# STM32H757_CM7 register map
File version: 1.3
CPU: CM7 r0p1, little endian, MPU, FPU, 4 interrupt priority bits
Registers are 32-bit, read-write, reset 0x0 unless marked. A register's access mark holds for its fields unless they carry their own. Offsets are from the block's base; [hi:lo] are bit positions; lines under a group give offsets from that group; {n}, {i} and the like mark numbered series; <NAME> marks a mode.

## SAI4 — SAI
Base 0x58005400
Same registers: SAI1 0x40015800, SAI2 0x40015C00, SAI3 0x40016000
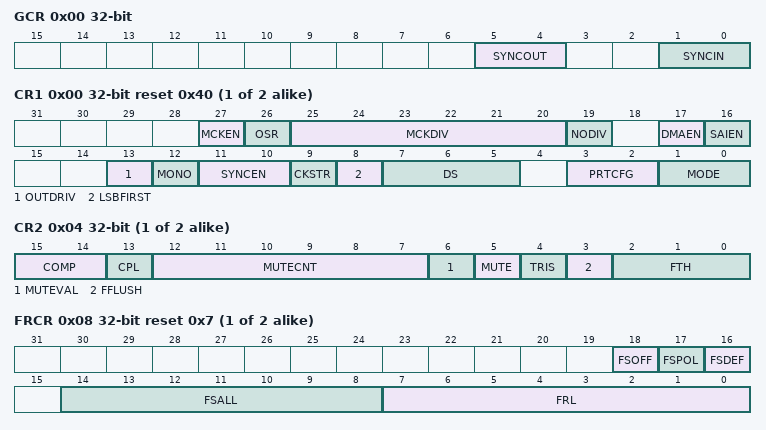
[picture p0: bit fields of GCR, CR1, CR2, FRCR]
0x00 GCR — Global configuration register
  [5:4] SYNCOUT — Synchronization outputs These bits are set and cleared by software.
  [1:0] SYNCIN — Synchronization inputs
0x04 CH{x} (x=A,B; step 0x20) group — Cluster CH{x}, containing ?CR1, ?CR2, ?FRCR, ?SLOTR, ?IM, ?SR, ?CLRFR, ?DR
  0x00 CR1 reset 0x40 — Configuration register 1
    [27] MCKEN — Master clock generation enable
    [26] OSR — Oversampling ratio for master clock
    [25:20] MCKDIV — Master clock divider. These bits are set and cleared by software. These bits are meaningless when the audio block operates in slave mode. They have to be configured when the audio block is disabled. Others: the master clock frequency is calculated accordingly to the following formula:
    [19] NODIV — No fixed divider between MCLK and FS
      0=MasterClock (MCLK output is enabled. Forces the ratio between FS and MCLK to 256 or 512 according to the OSR value); 1=NoDiv (MCLK output enable set by the MCKEN bit (where present, else 0). Ratio between FS and MCLK depends on FRL.)
    [17] DMAEN — DMA enable. This bit is set and cleared by software. Note: Since the audio block defaults to operate as a transmitter after reset, the MODE[1:0] bits must be configured before setting DMAEN to avoid a DMA request in receiver mode.
      0=Disabled (DMA disabled); 1=Enabled (DMA enabled)
    [16] SAIEN — Audio block enable where x is A or B. This bit is set by software. To switch off the audio block, the application software must program this bit to 0 and poll the bit till it reads back 0, meaning that the block is completely disabled. Before setting this bit to 1, check that it is set to 0, otherwise the enable command will not be taken into account. This bit allows to control the state of SAIx audio block. If it is disabled when an audio frame transfer is ongoing, the ongoing transfer completes and the cell is fully disabled at the end of this audio frame transfer. Note: When SAIx block is configured in master mode, the clock must be present on the input of SAIx before setting SAIXEN bit.
      0=Disabled (SAI audio block disabled); 1=Enabled (SAI audio block enabled)
    [13] OUTDRIV — Output drive. This bit is set and cleared by software. Note: This bit has to be set before enabling the audio block and after the audio block configuration.
      0=OnStart (Audio block output driven when SAIEN is set); 1=Immediately (Audio block output driven immediately after the setting of this bit)
    [12] MONO — Mono mode. This bit is set and cleared by software. It is meaningful only when the number of slots is equal to 2. When the mono mode is selected, slot 0 data are duplicated on slot 1 when the audio block operates as a transmitter. In reception mode, the slot1 is discarded and only the data received from slot 0 are stored. Refer to Section: Mono/stereo mode for more details.
      0=Stereo mode; 1=Mono mode
    [11:10] SYNCEN — Synchronization enable. These bits are set and cleared by software. They must be configured when the audio sub-block is disabled. Note: The audio sub-block should be configured as asynchronous when SPDIF mode is enabled.
      0=Asynchronous (audio sub-block in asynchronous mode); 1=Internal (audio sub-block is synchronous with the other internal audio sub-block. In this case, the audio sub-block must be configured in slave mode); 2=External (audio sub-block is synchronous with an external SAI embedded peripheral. In this case the audio sub-block should be configured in Slave mode)
    [9] CKSTR — Clock strobing edge. This bit is set and cleared by software. It must be configured when the audio block is disabled. This bit has no meaning in SPDIF audio protocol.
      0=FallingEdge (Data strobing edge is falling edge of SCK); 1=RisingEdge (Data strobing edge is rising edge of SCK)
    [8] LSBFIRST — Least significant bit first. This bit is set and cleared by software. It must be configured when the audio block is disabled. This bit has no meaning in AC97 audio protocol since AC97 data are always transferred with the MSB first. This bit has no meaning in SPDIF audio protocol since in SPDIF data are always transferred with LSB first.
      0=MsbFirst (Data are transferred with MSB first); 1=LsbFirst (Data are transferred with LSB first)
    [7:5] DS — Data size. These bits are set and cleared by software. These bits are ignored when the SPDIF protocols are selected (bit PRTCFG[1:0]), because the frame and the data size are fixed in such case. When the companding mode is selected through COMP[1:0] bits, DS[1:0] are ignored since the data size is fixed to 8 bits by the algorithm. These bits must be configured when the audio block is disabled.
      2=Bit8 (8 bits); 3=Bit10 (10 bits); 4=Bit16 (16 bits); 5=Bit20 (20 bits); 6=Bit24 (24 bits); 7=Bit32 (32 bits)
    [3:2] PRTCFG — Protocol configuration. These bits are set and cleared by software. These bits have to be configured when the audio block is disabled.
      0=Free protocol. Free protocol allows to use the powerful configuration of the audio block to address a specific audio protocol; 1=SPDIF protocol; 2=AC’97 protocol
    [1:0] MODE — SAIx audio block mode immediately
      0=MasterTx (Master transmitter); 1=MasterRx (Master receiver); 2=SlaveTx (Slave transmitter); 3=SlaveRx (Slave receiver)
  0x04 CR2 access per field — Configuration register 2
    [15:14] COMP rw — Companding mode. These bits are set and cleared by software. The -Law and the A-Law log are a part of the CCITT G.711 recommendation, the type of complement that will be used depends on CPL bit. The data expansion or data compression are determined by the state of bit MODE[0]. The data compression is applied if the audio block is configured as a transmitter. The data expansion is automatically applied when the audio block is configured as a receiver. Refer to Section: Companding mode for more details. Note: Companding mode is applicable only when TDM is selected.
      0=No companding algorithm; 2=MuLaw (μ-Law algorithm); 3=A-Law algorithm
    [13] CPL rw — Complement bit. This bit is set and cleared by software. It defines the type of complement to be used for companding mode Note: This bit has effect only when the companding mode is -Law algorithm or A-Law algorithm.
      0=OnesComplement (1’s complement representation); 1=TwosComplement (2’s complement representation)
    [12:7] MUTECNT rw — Mute counter. These bits are set and cleared by software. They are used only in reception mode. The value set in these bits is compared to the number of consecutive mute frames detected in reception. When the number of mute frames is equal to this value, the flag MUTEDET will be set and an interrupt will be generated if bit MUTEDETIE is set. Refer to Section: Mute mode for more details.
    [6] MUTEVAL rw — Mute value. This bit is set and cleared by software.It must be written before enabling the audio block: SAIXEN. This bit is meaningful only when the audio block operates as a transmitter, the number of slots is lower or equal to 2 and the MUTE bit is set. If more slots are declared, the bit value sent during the transmission in mute mode is equal to 0, whatever the value of MUTEVAL. if the number of slot is lower or equal to 2 and MUTEVAL = 1, the MUTE value transmitted for each slot is the one sent during the previous frame. Refer to Section: Mute mode for more details. Note: This bit is meaningless and should not be used for SPDIF audio blocks.
      0=SendZero (Bit value 0 is sent during the mute mode); 1=SendLast (Last values are sent during the mute mode)
    [5] MUTE rw — Mute. This bit is set and cleared by software. It is meaningful only when the audio block operates as a transmitter. The MUTE value is linked to value of MUTEVAL if the number of slots is lower or equal to 2, or equal to 0 if it is greater than 2. Refer to Section: Mute mode for more details. Note: This bit is meaningless and should not be used for SPDIF audio blocks.
      0=Disabled (No mute mode); 1=Enabled (Mute mode enabled)
    [4] TRIS rw — Tristate management on data line. This bit is set and cleared by software. It is meaningful only if the audio block is configured as a transmitter. This bit is not used when the audio block is configured in SPDIF mode. It should be configured when SAI is disabled. Refer to Section: Output data line management on an inactive slot for more details.
    [3] FFLUSH wo — FIFO flush. This bit is set by software. It is always read as 0. This bit should be configured when the SAI is disabled.
      0=NoFlush (No FIFO flush); 1=Flush (FIFO flush. Programming this bit to 1 triggers the FIFO Flush. All the internal FIFO pointers (read and write) are cleared)
    [2:0] FTH rw — FIFO threshold. This bit is set and cleared by software.
      0=Empty (FIFO empty); 1=Quarter1 (1⁄4 FIFO); 2=Quarter2 (1⁄2 FIFO); 3=Quarter3 (3⁄4 FIFO); 4=Full (FIFO full)
  0x08 FRCR reset 0x7 — This register has no meaning in AC97 and SPDIF audio protocol
    [18] FSOFF — Frame synchronization offset. This bit is set and cleared by software. It is meaningless and is not used in AC97 or SPDIF audio block configuration. This bit must be configured when the audio block is disabled.
      0=OnFirst (FS is asserted on the first bit of the slot 0); 1=BeforeFirst (FS is asserted one bit before the first bit of the slot 0)
    [17] FSPOL — Frame synchronization polarity. This bit is set and cleared by software. It is used to configure the level of the start of frame on the FS signal. It is meaningless and is not used in AC97 or SPDIF audio block configuration. This bit must be configured when the audio block is disabled.
      0=FallingEdge (FS is active low (falling edge)); 1=RisingEdge (FS is active high (rising edge))
    [16] FSDEF — Frame synchronization definition. This bit is set and cleared by software. When the bit is set, the number of slots defined in the SAI_xSLOTR register has to be even. It means that half of this number of slots will be dedicated to the left channel and the other slots for the right channel (e.g: this bit has to be set for I2S or MSB/LSB-justified protocols...). This bit is meaningless and is not used in AC97 or SPDIF audio block configuration. It must be configured when the audio block is disabled.
    [14:8] FSALL — Frame synchronization active level length. These bits are set and cleared by software. They specify the length in number of bit clock (SCK) + 1 (FSALL[6:0] + 1) of the active level of the FS signal in the audio frame These bits are meaningless and are not used in AC97 or SPDIF audio block configuration. They must be configured when the audio block is disabled.
    [7:0] FRL — Frame length. These bits are set and cleared by software. They define the audio frame length expressed in number of SCK clock cycles: the number of bits in the frame is equal to FRL[7:0] + 1. The minimum number of bits to transfer in an audio frame must be equal to 8, otherwise the audio block will behaves in an unexpected way. This is the case when the data size is 8 bits and only one slot 0 is defined in NBSLOT[4:0] of SAI_xSLOTR register (NBSLOT[3:0] = 0000). In master mode, if the master clock (available on MCLK_x pin) is used, the frame length should be aligned with a number equal to a power of 2, ranging from 8 to 256. When the master clock is not used (NODIV = 1), it is recommended to program the frame length to an value ranging from 8 to 256. These bits are meaningless and are not used in AC97 or SPDIF audio block configuration.
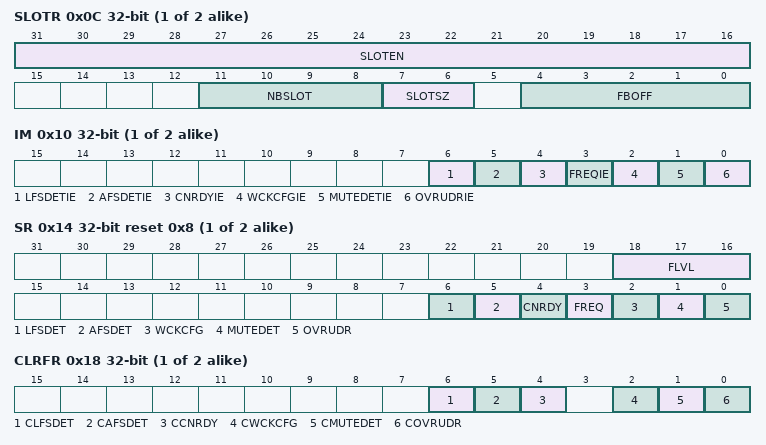
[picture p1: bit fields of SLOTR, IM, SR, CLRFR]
  0x0C SLOTR — This register has no meaning in AC97 and SPDIF audio protocol
    [31:16] SLOTEN — Slot enable. These bits are set and cleared by software. Each SLOTEN bit corresponds to a slot position from 0 to 15 (maximum 16 slots). The slot must be enabled when the audio block is disabled. They are ignored in AC97 or SPDIF mode.
      0=Inactive slot; 1=Active slot
    [11:8] NBSLOT — Number of slots in an audio frame. These bits are set and cleared by software. The value set in this bitfield represents the number of slots + 1 in the audio frame (including the number of inactive slots). The maximum number of slots is 16. The number of slots should be even if FSDEF bit in the SAI_xFRCR register is set. The number of slots must be configured when the audio block is disabled. They are ignored in AC97 or SPDIF mode.
    [7:6] SLOTSZ — Slot size This bits is set and cleared by software. The slot size must be higher or equal to the data size. If this condition is not respected, the behavior of the SAI will be undetermined. Refer to Section: Output data line management on an inactive slot for information on how to drive SD line. These bits must be set when the audio block is disabled. They are ignored in AC97 or SPDIF mode.
      0=DataSize (The slot size is equivalent to the data size (specified in DS[3:0] in the SAI_xCR1 register)); 1=Bit16 (16-bit); 2=Bit32 (32-bit)
    [4:0] FBOFF — First bit offset These bits are set and cleared by software. The value set in this bitfield defines the position of the first data transfer bit in the slot. It represents an offset value. In transmission mode, the bits outside the data field are forced to 0. In reception mode, the extra received bits are discarded. These bits must be set when the audio block is disabled. They are ignored in AC97 or SPDIF mode.
  0x10 IM — Interrupt mask register 2
    [all] fields
      0=Disabled (Interrupt is disabled); 1=Enabled (Interrupt is enabled)
    [6] LFSDETIE — Late frame synchronization detection interrupt enable. This bit is set and cleared by software. When this bit is set, an interrupt will be generated if the LFSDET bit is set in the SAI_xSR register. This bit is meaningless in AC97, SPDIF mode or when the audio block operates as a master.
    [5] AFSDETIE — Anticipated frame synchronization detection interrupt enable. This bit is set and cleared by software. When this bit is set, an interrupt will be generated if the AFSDET bit in the SAI_xSR register is set. This bit is meaningless in AC97, SPDIF mode or when the audio block operates as a master.
    [4] CNRDYIE — Codec not ready interrupt enable (AC97). This bit is set and cleared by software. When the interrupt is enabled, the audio block detects in the slot 0 (tag0) of the AC97 frame if the Codec connected to this line is ready or not. If it is not ready, the CNRDY flag in the SAI_xSR register is set and an interruption i generated. This bit has a meaning only if the AC97 mode is selected through PRTCFG[1:0] bits and the audio block is operates as a receiver.
    [3] FREQIE — FIFO request interrupt enable. This bit is set and cleared by software. When this bit is set, an interrupt is generated if the FREQ bit in the SAI_xSR register is set. Since the audio block defaults to operate as a transmitter after reset, the MODE bit must be configured before setting FREQIE to avoid a parasitic interruption in receiver mode,
    [2] WCKCFGIE — Wrong clock configuration interrupt enable. This bit is set and cleared by software. This bit is taken into account only if the audio block is configured as a master (MODE[1] = 0) and NODIV = 0. It generates an interrupt if the WCKCFG flag in the SAI_xSR register is set. Note: This bit is used only in TDM mode and is meaningless in other modes.
    [1] MUTEDETIE — Mute detection interrupt enable. This bit is set and cleared by software. When this bit is set, an interrupt is generated if the MUTEDET bit in the SAI_xSR register is set. This bit has a meaning only if the audio block is configured in receiver mode.
    [0] OVRUDRIE — Overrun/underrun interrupt enable. This bit is set and cleared by software. When this bit is set, an interrupt is generated if the OVRUDR bit in the SAI_xSR register is set.
  0x14 SR ro reset 0x8 — Status register
    [18:16] FLVL — FIFO level threshold. This bit is read only. The FIFO level threshold flag is managed only by hardware and its setting depends on SAI block configuration (transmitter or receiver mode). If the SAI block is configured as transmitter: If SAI block is configured as receiver:
      on read: 0=Empty (FIFO empty); 1=Quarter1 (FIFO <= 1⁄4 but not empty); 2=Quarter2 (1⁄4 < FIFO <= 1⁄2); 3=Quarter3 (1⁄2 < FIFO <= 3⁄4); 4=Quarter4 (3⁄4 < FIFO but not full); 5=Full (FIFO full)
    [6] LFSDET — Late frame synchronization detection. This bit is read only. This flag can be set only if the audio block is configured in slave mode. It is not used in AC97 or SPDIF mode. It can generate an interrupt if LFSDETIE bit is set in the SAI_xIM register. This flag is cleared when the software sets bit CLFSDET in SAI_xCLRFR register
      on read: 0=NoError; 1=NoSync (Frame synchronization signal is not present at the right time)
    [5] AFSDET — Anticipated frame synchronization detection. This bit is read only. This flag can be set only if the audio block is configured in slave mode. It is not used in AC97or SPDIF mode. It can generate an interrupt if AFSDETIE bit is set in SAI_xIM register. This flag is cleared when the software sets CAFSDET bit in SAI_xCLRFR register.
      on read: 0=NoError; 1=EarlySync (Frame synchronization signal is detected earlier than expected)
    [4] CNRDY — Codec not ready. This bit is read only. This bit is used only when the AC97 audio protocol is selected in the SAI_xCR1 register and configured in receiver mode. It can generate an interrupt if CNRDYIE bit is set in SAI_xIM register. This flag is cleared when the software sets CCNRDY bit in SAI_xCLRFR register.
      on read: 0=Ready (External AC’97 Codec is ready); 1=NotReady (External AC’97 Codec is not ready)
    [3] FREQ — FIFO request. This bit is read only. The request depends on the audio block configuration: If the block is configured in transmission mode, the FIFO request is related to a write request operation in the SAI_xDR. If the block configured in reception, the FIFO request related to a read request operation from the SAI_xDR. This flag can generate an interrupt if FREQIE bit is set in SAI_xIM register.
      on read: 0=NoRequest (No FIFO request); 1=Request (FIFO request to read or to write the SAI_xDR)
    [2] WCKCFG — Wrong clock configuration flag. This bit is read only. This bit is used only when the audio block operates in master mode (MODE[1] = 0) and NODIV = 0. It can generate an interrupt if WCKCFGIE bit is set in SAI_xIM register. This flag is cleared when the software sets CWCKCFG bit in SAI_xCLRFR register.
      on read: 0=Correct (Clock configuration is correct); 1=Wrong (Clock configuration does not respect the rule concerning the frame length specification)
    [1] MUTEDET — Mute detection. This bit is read only. This flag is set if consecutive 0 values are received in each slot of a given audio frame and for a consecutive number of audio frames (set in the MUTECNT bit in the SAI_xCR2 register). It can generate an interrupt if MUTEDETIE bit is set in SAI_xIM register. This flag is cleared when the software sets bit CMUTEDET in the SAI_xCLRFR register.
      on read: 0=No MUTE detection on the SD input line; 1=MUTE value detected on the SD input line (0 value) for a specified number of consecutive audio frame
    [0] OVRUDR — Overrun / underrun. This bit is read only. The overrun and underrun conditions can occur only when the audio block is configured as a receiver and a transmitter, respectively. It can generate an interrupt if OVRUDRIE bit is set in SAI_xIM register. This flag is cleared when the software sets COVRUDR bit in SAI_xCLRFR register.
      on read: 0=NoError (No overrun/underrun error); 1=Overrun/underrun error detection
  0x18 CLRFR wo — Clear flag register
    [6] CLFSDET — Clear late frame synchronization detection flag. This bit is write only. Programming this bit to 1 clears the LFSDET flag in the SAI_xSR register. This bit is not used in AC97or SPDIF mode Reading this bit always returns the value 0.
      on write: 1=Clears the LFSDET flag
    [5] CAFSDET — Clear anticipated frame synchronization detection flag. This bit is write only. Programming this bit to 1 clears the AFSDET flag in the SAI_xSR register. It is not used in AC97or SPDIF mode. Reading this bit always returns the value 0.
      on write: 1=Clears the AFSDET flag
    [4] CCNRDY — Clear Codec not ready flag. This bit is write only. Programming this bit to 1 clears the CNRDY flag in the SAI_xSR register. This bit is used only when the AC97 audio protocol is selected in the SAI_xCR1 register. Reading this bit always returns the value 0.
      on write: 1=Clears the CNRDY flag
    [2] CWCKCFG — Clear wrong clock configuration flag. This bit is write only. Programming this bit to 1 clears the WCKCFG flag in the SAI_xSR register. This bit is used only when the audio block is set as master (MODE[1] = 0) and NODIV = 0 in the SAI_xCR1 register. Reading this bit always returns the value 0.
      on write: 1=Clears the WCKCFG flag
    [1] CMUTEDET — Mute detection flag. This bit is write only. Programming this bit to 1 clears the MUTEDET flag in the SAI_xSR register. Reading this bit always returns the value 0.
      on write: 1=Clears the MUTEDET flag
    [0] COVRUDR — Clear overrun / underrun. This bit is write only. Programming this bit to 1 clears the OVRUDR flag in the SAI_xSR register. Reading this bit always returns the value 0.
      on write: 1=Clears the OVRUDR flag
  0x1C DR — Data register
    [31:0] DATA — Data A write to this register loads the FIFO provided the FIFO is not full. A read from this register empties the FIFO if the FIFO is not empty.
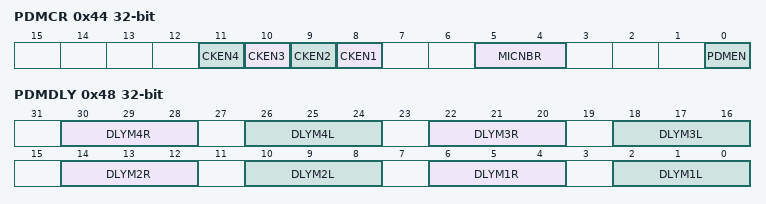
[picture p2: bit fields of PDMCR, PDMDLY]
0x44 PDMCR — PDM control register
  [n+7] CKEN{n} (n=1..4) — Clock enable of bitstream clock number {n}
  [5:4] MICNBR — Number of microphones
  [0] PDMEN — PDM enable
0x48 PDMDLY — PDM delay register
  [30:28] DLYM4R — Delay line for second microphone of pair 4
  [26:24] DLYM4L — Delay line for first microphone of pair 4
  [22:20] DLYM3R — Delay line for second microphone of pair 3
  [18:16] DLYM3L — Delay line for first microphone of pair 3
  [14:12] DLYM2R — Delay line for second microphone of pair 2
  [10:8] DLYM2L — Delay line for first microphone of pair 2
  [6:4] DLYM1R — Delay line adjust for second microphone of pair 1
  [2:0] DLYM1L — Delay line adjust for first microphone of pair 1
